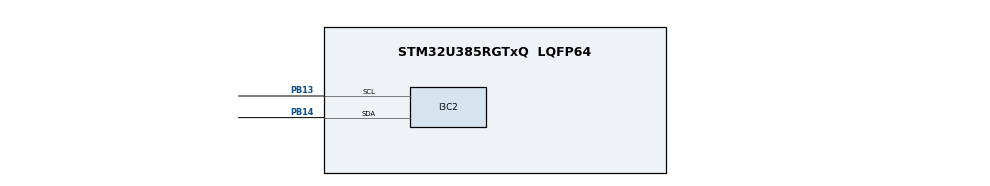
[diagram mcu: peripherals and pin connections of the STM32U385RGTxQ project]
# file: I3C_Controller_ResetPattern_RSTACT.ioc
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CORTEX_M33_NS.userName=CORTEX_M33
I3C2.AutonomousMode=AUTONOMOUS_MODE_DISABLE
I3C2.BusFreeDuration=432
I3C2.DutyCycleI3C=50
I3C2.FrequencyI3C=12500
I3C2.RXFIFOThreshold=HAL_I3C_RXFIFO_THRESHOLD_4_4
I3C2.Register0=0x00230303
I3C2.Register1=0x0013005e
I3C2.SCLI3CHighDuration=0x03
I3C2.SCLODLowDuration=0x23
I3C2.SCLPPLowDuration=0x03
I3C2.SCL_OD_Freq=2400
I3C2.SCL_PP_Freq=12000
I3C2.TXFIFOThreshold=HAL_I3C_TXFIFO_THRESHOLD_4_4
I3C2.hexBusFreeDuration=0x13
I3C2.hexBusIdleDuration=0x5e
Mcu.Family=STM32U3
Mcu.Name=STM32U385RGTxQ
Mcu.Package=LQFP64
NVIC.I3C2_ER_IRQn=true\:0\:0\:false\:false\:true\:true\:true\:true
NVIC.I3C2_EV_IRQn=true\:0\:0\:false\:false\:true\:true\:true\:true
NVIC.PriorityGroup=NVIC_PRIORITYGROUP_4
PB13.Mode=Controller
PB13.Signal=I3C2_SCL
PB14.Mode=Controller
PB14.Signal=I3C2_SDA
ProjectManager.HeapSize=0x200
ProjectManager.StackSize=0x400
ProjectManager.TargetToolchain=EWARM V9.20
RCC.ADCFreq_Value=96000000
RCC.AHBFreq_Value=96000000
RCC.APB1Freq_Value=96000000
RCC.APB1TimFreq_Value=96000000
RCC.APB2Freq_Value=96000000
RCC.APB2TimFreq_Value=96000000
RCC.APB3Freq_Value=96000000
RCC.CortexFreq_Value=12000000
RCC.HCLKFreq_Value=96000000
RCC.HSE_VALUE=16000000
RCC.HSI48_VALUE=48000000
RCC.HSI_VALUE=16000000
RCC.I3C2CLockSelection=RCC_I3C2CLKSOURCE_MSIK
RCC.LSE_VALUE=32768
RCC.LSIDIV_VALUE=32000
RCC.MSISDIV=RCC_MSI_DIV1
RCC.SYSCLKFreq_VALUE=96000000
RCC.USBFreq_Value=96000000
VP_ICACHE_VS_ICACHE.Mode=DirectMappedCache
VP_MEMORYMAP_VS_MEMORYMAP.Mode=CurAppReg
VP_PWR_VS_DBSignals.Mode=DisableDeadBatterySignals
VP_PWR_VS_LPOM.Mode=PowerOptimisation
VP_PWR_VS_SECSignals.Mode=Security/Privilege
board=custom

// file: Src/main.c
/* USER CODE BEGIN Header */
/**
  ******************************************************************************
  * @file           : I3C/I3C_Controller_ResetPattern_RSTACT/Src/main.c
  * @brief          : This sample code shows how to use STM32U3xx I3C HAL API
  *                   as Controller to transmit Reset Pattern at the end of RSTACT CCC.
  *                   The communication process is based on IT transfer.
  *                   The communication is done using 2 Boards.
  ******************************************************************************
  * @attention
  *
  * Copyright (c) 2024 STMicroelectronics.
  * All rights reserved.
  *
  * This software is licensed under terms that can be found in the LICENSE file
  * in the root directory of this software component.
  * If no LICENSE file comes with this software, it is provided AS-IS.
  *
  ******************************************************************************
  */
/* USER CODE END Header */
#include "main.h"

/* USER CODE BEGIN Includes */
#include "desc_target1.h"

/* USER CODE END Includes */

/* USER CODE BEGIN PD */
#define I3C_IDX_FRAME_1         0U  /* Index of Frame 1 */
/* USER CODE END PD */

I3C_HandleTypeDef hi3c2;

/* USER CODE BEGIN PV */
/* Context buffer related to Frame context, contain different buffer value for a communication */
I3C_XferTypeDef aContextBuffers[2];

/* USER CODE BEGIN PV */
/* Number of Targets detected during DAA procedure */
__IO uint32_t uwTargetCount = 0;

/* Buffer used for transmission */
uint8_t aTxBuffer[0xF];

/* Buffer used by HAL to compute control data for the Private Communication */
uint32_t aControlBuffer[0xF];

/* Array contain RSTACT CCC defining byte */
uint8_t aRSTACT_defining_byte[1] = {0x01};

/* Array contain targets descriptor */
TargetDesc_TypeDef *aTargetDesc[1] = \
                          {
                            &TargetDesc1       /* DEVICE_ID1 */
                          };

/* Array contain RSTACT CCC direct descriptor */
I3C_CCCTypeDef RSTACT_DIRECT_Descriptor[1] = \
{
  /*   Target Addr              CCC Value       CCC data + defbyte pointer  CCC size + defbyte         Direction        */
  {TARGET1_DYN_ADDR,     I3C_DIRECT_RSTACT_CCC, {aRSTACT_defining_byte,            1U},                HAL_I3C_DIRECTION_WRITE},
};

/* Buffer that contain payload data, mean PID, BCR, DCR */
uint8_t aPayloadBuffer[64*COUNTOF(aTargetDesc)];

/* USER CODE END PV */

void SystemClock_Config(void);
static void MX_GPIO_Init(void);
static void MX_I3C2_Init(void);
static void MX_ICACHE_Init(void);

int main(void)
{

  /* MCU Configuration--------------------------------------------------------*/

  /* Reset of all peripherals, Initializes the Flash interface and the Systick. */
  HAL_Init();

  /* Configure the system clock */
  SystemClock_Config();

  /* Initialize all configured peripherals */
  MX_GPIO_Init();
  MX_I3C2_Init();
  MX_ICACHE_Init();
  /* USER CODE BEGIN 2 */
  /* Configure LD2 */
  BSP_LED_Init(LD2);

  /* Configure USER push-button */
  BSP_PB_Init(BUTTON_USER, BUTTON_MODE_GPIO);

  /* Wait for USER push-button press before starting the Communication   */
  while (BSP_PB_GetState(BUTTON_USER) != GPIO_PIN_RESET)
  {
  }

  /* Wait for USER push-button release before starting the Communication */
  while (BSP_PB_GetState(BUTTON_USER) != GPIO_PIN_SET)
  {
  }

  /*##- Start the transmission process ###################################*/
  /* Assign dynamic address processus */
  if (HAL_I3C_Ctrl_DynAddrAssign_IT(&hi3c2, I3C_ONLY_ENTDAA) != HAL_OK)
  {
    /* Error_Handler() function is called when error occurs. */
    Error_Handler();
  }

  /*##- Wait for the end of the transfer #################################*/
  /*  Before starting a new communication transfer, you need to check the current
  state of the peripheral; if it s busy you need to wait for the end of current
  transfer before starting a new one.
  For simplicity reasons, this example is just waiting till the end of the
  transfer, but application may perform other tasks while transfer operation
  is ongoing. */
  while (HAL_I3C_GetState(&hi3c2) != HAL_I3C_STATE_READY)
  {
  }

  /*## Insert reset pattern at the end of a Frame ########################*/
  if (HAL_I3C_Ctrl_SetConfigResetPattern(&hi3c2, HAL_I3C_RESET_PATTERN_ENABLE) != HAL_OK)
  {
    /* Error_Handler() function is called when error occurs. */
    Error_Handler();
  }

  /*##- Prepare context buffers process ##################################*/
  /* Prepare Transmit context buffer with the different parameters */
  aContextBuffers[I3C_IDX_FRAME_1].CtrlBuf.pBuffer  = aControlBuffer;
  aContextBuffers[I3C_IDX_FRAME_1].CtrlBuf.Size = 2U;
  aContextBuffers[I3C_IDX_FRAME_1].TxBuf.pBuffer       = aTxBuffer;
  aContextBuffers[I3C_IDX_FRAME_1].TxBuf.Size      = 1U;

  /*##- Add context buffer transmit in Frame context #####################*/
  if (HAL_I3C_AddDescToFrame(&hi3c2,
                             RSTACT_DIRECT_Descriptor,
                             NULL,
                             &aContextBuffers[I3C_IDX_FRAME_1],
                             1,
                             I3C_DIRECT_WITH_DEFBYTE_STOP) != HAL_OK)
  {
    /* Error_Handler() function is called when error occurs. */
    Error_Handler();
  }

  /* Wait for USER push-button press before starting the Communication   */
  while (BSP_PB_GetState(BUTTON_USER) != GPIO_PIN_RESET)
  {
  }

  /* Wait for USER push-button release before starting the Communication */
  while (BSP_PB_GetState(BUTTON_USER) != GPIO_PIN_SET)
  {
  }

  /*##- Start the transmission process ###################################*/
  /* Transmit private data processus */
  if (HAL_I3C_Ctrl_TransmitCCC_IT(&hi3c2, &aContextBuffers[I3C_IDX_FRAME_1]) != HAL_OK)
  {
    /* Error_Handler() function is called when error occurs. */
    Error_Handler();
  }

  /*##- Wait for the end of the transfer #################################*/
  /*  Before starting a new communication transfer, you need to check the current
  state of the peripheral; if it s busy you need to wait for the end of current
  transfer before starting a new one.
  For simplicity reasons, this example is just waiting till the end of the
  transfer, but application may perform other tasks while transfer operation
  is ongoing. */
  while (HAL_I3C_GetState(&hi3c2) != HAL_I3C_STATE_READY)
  {
  }

  /* USER CODE END 2 */

  /* Infinite loop */
  while (1)
  {

  }
}

void SystemClock_Config(void)
{
  RCC_OscInitTypeDef RCC_OscInitStruct = {0};
  RCC_ClkInitTypeDef RCC_ClkInitStruct = {0};

  /** Configure the System Power Supply
  */
  if (HAL_PWREx_ConfigSupply(PWR_SMPS_SUPPLY) != HAL_OK)
  {
    Error_Handler();
  }

  /** Enable Epod Booster
  */
  if (HAL_RCCEx_EpodBoosterClkConfig(RCC_EPODBOOSTER_SOURCE_MSIS, RCC_EPODBOOSTER_DIV1) != HAL_OK)
  {
    Error_Handler();
  }
  if (HAL_PWREx_EnableEpodBooster() != HAL_OK)
  {
    Error_Handler();
  }

  /** Configure the main internal regulator output voltage
  */
  if (HAL_PWREx_ControlVoltageScaling(PWR_REGULATOR_VOLTAGE_SCALE1) != HAL_OK)
  {
    Error_Handler();
  }

  /** Set Flash latency before increasing MSIS
  */
  __HAL_FLASH_SET_LATENCY(FLASH_LATENCY_2);

  /** Initializes the CPU, AHB and APB buses clocks
  */
  RCC_OscInitStruct.OscillatorType = RCC_OSCILLATORTYPE_MSIS|RCC_OSCILLATORTYPE_MSIK;
  RCC_OscInitStruct.MSISState = RCC_MSI_ON;
  RCC_OscInitStruct.MSISSource = RCC_MSI_RC0;
  RCC_OscInitStruct.MSISDiv = RCC_MSI_DIV1;
  RCC_OscInitStruct.MSIKState = RCC_MSI_ON;
  RCC_OscInitStruct.MSIKSource = RCC_MSI_RC0;
  RCC_OscInitStruct.MSIKDiv = RCC_MSI_DIV1;

  if (HAL_RCC_OscConfig(&RCC_OscInitStruct) != HAL_OK)
  {
    Error_Handler();
  }

  /** Initializes the CPU, AHB and APB buses clocks
  */
  RCC_ClkInitStruct.ClockType = RCC_CLOCKTYPE_HCLK|RCC_CLOCKTYPE_SYSCLK
                              |RCC_CLOCKTYPE_PCLK1|RCC_CLOCKTYPE_PCLK2
                              |RCC_CLOCKTYPE_PCLK3;
  RCC_ClkInitStruct.SYSCLKSource = RCC_SYSCLKSOURCE_MSIS;
  RCC_ClkInitStruct.AHBCLKDivider = RCC_SYSCLK_DIV1;
  RCC_ClkInitStruct.APB1CLKDivider = RCC_HCLK_DIV1;
  RCC_ClkInitStruct.APB2CLKDivider = RCC_HCLK_DIV1;
  RCC_ClkInitStruct.APB3CLKDivider = RCC_HCLK_DIV1;

  if (HAL_RCC_ClockConfig(&RCC_ClkInitStruct, FLASH_LATENCY_2) != HAL_OK)
  {
    Error_Handler();
  }
}

static void MX_I3C2_Init(void)
{

  I3C_FifoConfTypeDef sFifoConfig = {0};
  I3C_CtrlConfTypeDef sCtrlConfig = {0};

  hi3c2.Instance = I3C2;
  hi3c2.Mode = HAL_I3C_MODE_CONTROLLER;
  hi3c2.Init.CtrlBusCharacteristic.SDAHoldTime = HAL_I3C_SDA_HOLD_TIME_0_5;
  hi3c2.Init.CtrlBusCharacteristic.WaitTime = HAL_I3C_OWN_ACTIVITY_STATE_0;
  hi3c2.Init.CtrlBusCharacteristic.SCLPPLowDuration = 0x03;
  hi3c2.Init.CtrlBusCharacteristic.SCLI3CHighDuration = 0x03;
  hi3c2.Init.CtrlBusCharacteristic.SCLODLowDuration = 0x23;
  hi3c2.Init.CtrlBusCharacteristic.SCLI2CHighDuration = 0x00;
  hi3c2.Init.CtrlBusCharacteristic.BusFreeDuration = 0x13;
  hi3c2.Init.CtrlBusCharacteristic.BusIdleDuration = 0x5e;
  if (HAL_I3C_Init(&hi3c2) != HAL_OK)
  {
    Error_Handler();
  }

  /** Configure FIFO
  */
  sFifoConfig.RxFifoThreshold = HAL_I3C_RXFIFO_THRESHOLD_4_4;
  sFifoConfig.TxFifoThreshold = HAL_I3C_TXFIFO_THRESHOLD_4_4;
  sFifoConfig.ControlFifo = HAL_I3C_CONTROLFIFO_DISABLE;
  sFifoConfig.StatusFifo = HAL_I3C_STATUSFIFO_DISABLE;
  if (HAL_I3C_SetConfigFifo(&hi3c2, &sFifoConfig) != HAL_OK)
  {
    Error_Handler();
  }

  /** Configure controller
  */
  sCtrlConfig.DynamicAddr = 0;
  sCtrlConfig.StallTime = 0x00;
  sCtrlConfig.HotJoinAllowed = DISABLE;
  sCtrlConfig.ACKStallState = DISABLE;
  sCtrlConfig.CCCStallState = DISABLE;
  sCtrlConfig.TxStallState = DISABLE;
  sCtrlConfig.RxStallState = DISABLE;
  sCtrlConfig.HighKeeperSDA = DISABLE;
  if (HAL_I3C_Ctrl_Config(&hi3c2, &sCtrlConfig) != HAL_OK)
  {
    Error_Handler();
  }

}

static void MX_ICACHE_Init(void)
{

  /** Enable instruction cache in 1-way (direct mapped cache)
  */
  if (HAL_ICACHE_ConfigAssociativityMode(ICACHE_1WAY) != HAL_OK)
  {
    Error_Handler();
  }
  if (HAL_ICACHE_Enable() != HAL_OK)
  {
    Error_Handler();
  }

}

static void MX_GPIO_Init(void)
{

  /* GPIO Ports Clock Enable */
  __HAL_RCC_GPIOB_CLK_ENABLE();

}

/* USER CODE BEGIN 4 */
/**
  * @brief I3C target request a dynamic address callback.
  *        The main objective of this user function is to check if a target request a dynamic address.
  *        if the case we should assign a dynamic address to the target.
  * @par Called functions
  * - HAL_I3C_TgtReqDynamicAddrCallback()
  * - HAL_I3C_Ctrl_SetDynamicAddress()
  * @retval None
  */
void HAL_I3C_TgtReqDynamicAddrCallback(I3C_HandleTypeDef *hi3c, uint64_t targetPayload)
{
  /* Update Payload on aTargetDesc */
  aTargetDesc[uwTargetCount]->TARGET_BCR_DCR_PID = targetPayload;

  /* Send associated dynamic address */
  HAL_I3C_Ctrl_SetDynAddr(hi3c, aTargetDesc[uwTargetCount++]->DYNAMIC_ADDR);
}

/**
  * @brief  Controller dynamic address assignment Complete callback.
  * @param  hi3c : [IN] Pointer to an I3C_HandleTypeDef structure that contains the configuration information
  *                     for the specified I3C.
  * @retval None
  */
void HAL_I3C_CtrlDAACpltCallback(I3C_HandleTypeDef *hi3c)
{
  /* Turn LD2 on: Transfer in transmission process is correct */
  BSP_LED_On(LD2);
}

/**
  * @brief  Controller Transmit Complete callback.
  * @param  hi3c : [IN] Pointer to an I3C_HandleTypeDef structure that contains the configuration information
  *                     for the specified I3C.
  * @retval None
  */
void HAL_I3C_CtrlTxCpltCallback(I3C_HandleTypeDef *hi3c)
{
  /* Toggle LD2: Transfer in transmission process is correct */
  BSP_LED_Toggle(LD2);
}

/* USER CODE END 4 */

void Error_Handler(void)
{
  /* USER CODE BEGIN Error_Handler_Debug */
  /* Error if LD2 is slowly blinking (1 sec. period) */
  while (1)
  {
    BSP_LED_Toggle(LD2);
    HAL_Delay(1000);
  }
  /* USER CODE END Error_Handler_Debug */
}
